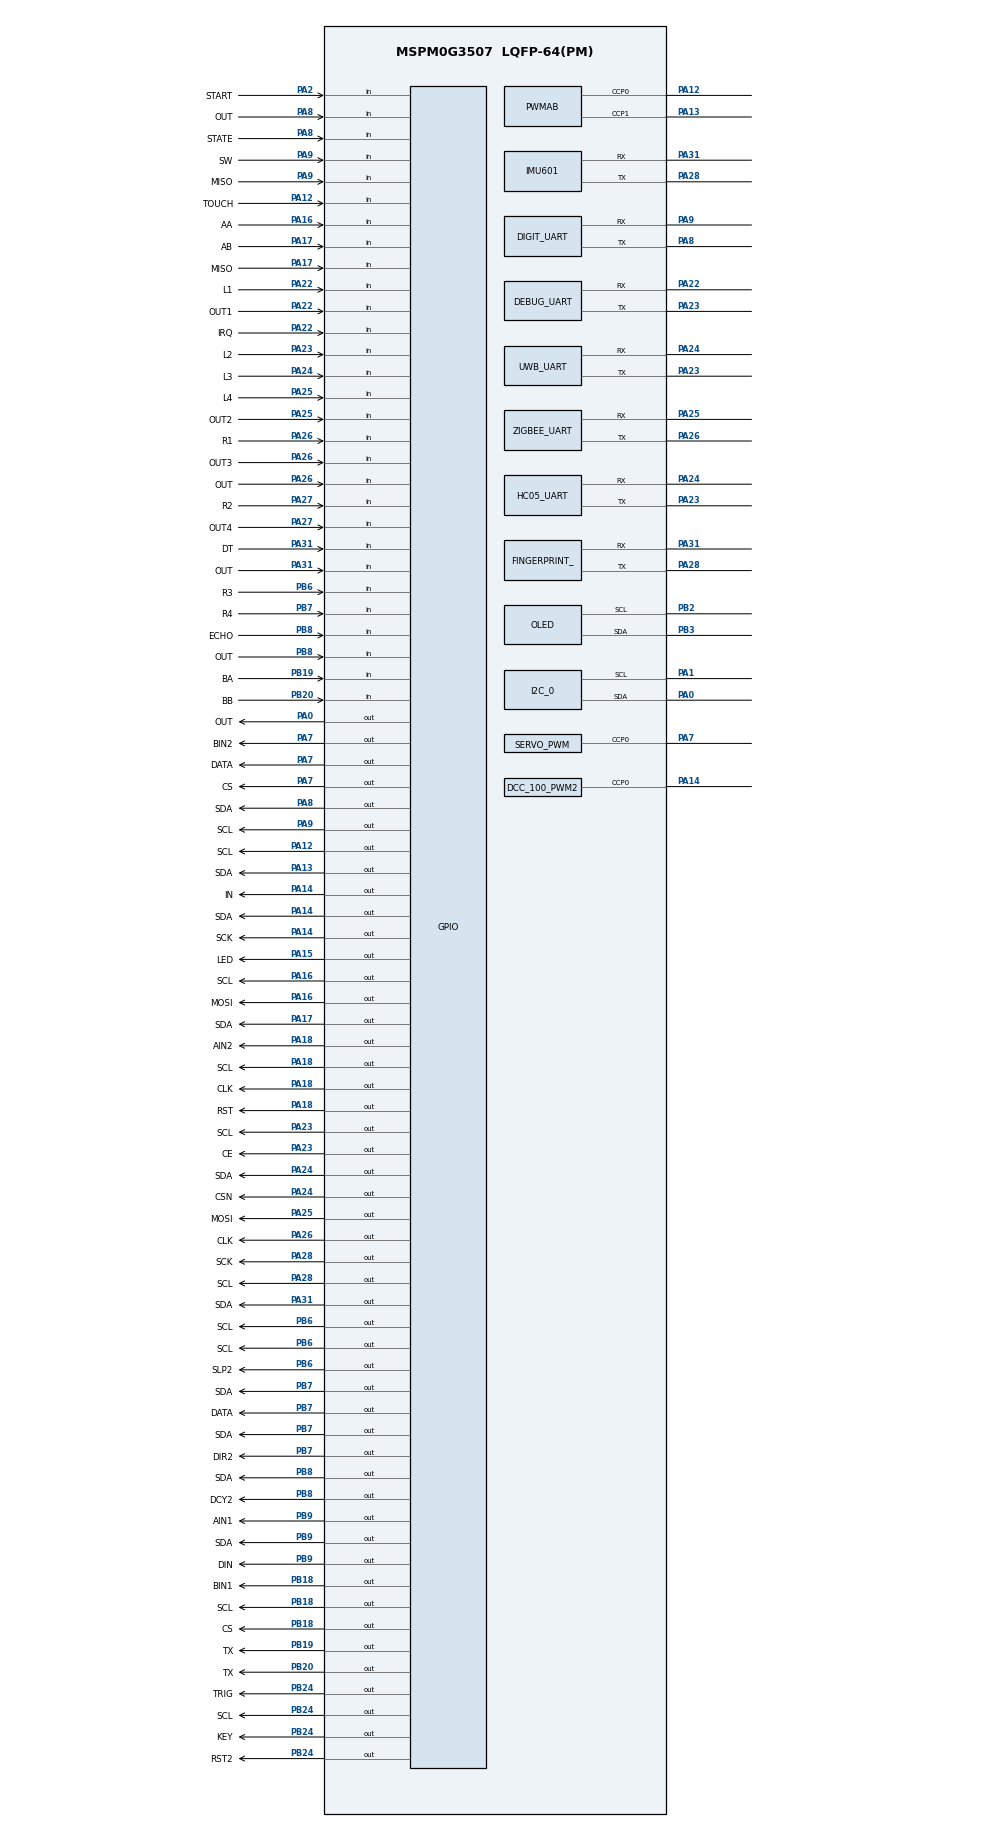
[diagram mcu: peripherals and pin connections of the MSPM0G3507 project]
/**
 * firstep mspm0 母版默认外设布局（地猛星 LCKFB-DMX 开发板，模块库默认引脚方案，
 * 编译闭环用；2026-08-14 地猛星化，工单 mspm0-master-dimx/01）。
 * 实例名/宏名与模块库代码一一对应（PWMAB/DC_MOTOR/IMU601/OLED/NTB/MOTOR_PID/
 * HUIDU/KEY/LED_BEEP/STEP_MOTOR/DCC_100_PWM2/I2C_0）；实际接线不同时改引脚名
 * 即可，实例名与宏名勿动。
 * 引脚方案（除 PB4/PB5 外全部在地猛星 2×20 排针上）：
 *   motor：PWMAB C0/C1→PA12/PA13、DC_MOTOR AIN1=PB9 AIN2=PA18 BIN1=PB18
 *   BIN2=PA7、编码器 AA=PA16 AB=PA17 BA=PB19 BB=PB20
 *   HUIDU：PA22-27/PB4/PB5（R3/R4 的 PB4/PB5 为 LaunchPad 遗留，地猛星未引出）
 *   KEY：PA2（板载 ROSC 偏置 100k 到地，按键与上拉共用此脚）
 *   LED_BEEP：PA15；IR_BEAM：PA8（红外对射 OUT，ir_beam 模块；与
 *   DIGIT_UART 默认重叠，同选时经引脚绑定消解）；IMU601：UART0 =
 *   PA28(TX)/PA31(RX)（板载 CH340E 占
 *   UART0 的 PA10/PA11，勿用）；DIGIT_UART：UART1 = PA8(TX)/PA9(RX)（K230 串口）
 *   OLED：I2C1 = PB3(SDA)/PB2(SCL)；I2C_0：I2C0 = PA0(SDA)/PA1(SCL)（MPU6050，
 *   复用板载 LED 脚——总线空闲高电平 LED 不亮，通信期间微闪；PA1 板载 4.7k 上拉，
 *   PA0 上拉未焊 R12，靠 MPU 板自带）
 *   STEP_MOTOR：RST2/SLP2/DIR2/DCY2 = PB24/PB6/PB7/PB8（全 GPIOB，
 *   STEP_MOTOR_PORT 整组 GPIOB）；DCC_100_PWM2：TIMG12 C0 = PA14（板上经
 *   LED2+15k 到地，PWM 输出时 LED 微亮，可忽略）
 *   JOYSTICK：SW = PA9（摇杆按键，上拉输入低有效；与 DIGIT_UART RX 默认
 *   重叠——手动摇杆与 K230 视觉同选概率最低，同选时经引脚绑定消解）；
 *   ADC12_0 八通道：MEM0 = PA24(A0_3) 归 adc 模块（us016/mq2 薄封装共读同槽），
 *   MEM1 = PA26(A0_1) / MEM2 = PA25(A0_2) 归 joystick 摇杆 X/Y（与
 *   ZIGBEE_UART 默认重叠——手动摇杆与无线身份/信标同选概率最低，同选时
 *   经引脚绑定消解；多 MEM 必须 sequence 模式，2026-09-05 SysConfig CLI
 *   实证），MEM3 = PA27(A0_0) 归 ir_distance（与 HUIDU R2 重叠——红外
 *   测距与灰度巡线同选概率最低），MEM4 = PB20(A0_6) 归 mq135、MEM5 =
 *   PB24(A0_5) 归 mq5（两件均独立通道，
 *   与 DC_MOTOR BB/SYN6288 TX、STEP_MOTOR RST2/SR04 TRIG/HC05 KEY/AT24C02 SCL
 *   重叠——MQ 系与运动控制/语音/记录常见同框概率最低；多路气体同选时物理
 *   通道独立、无共读冲突——mq2 为 MEM0 薄封装
 *   共读同槽，2026-09-08 实证 MEM4-7 通道/脚全合法），MEM6 = PA22(A0_7) 归
 *   flame 火焰传感（独立通道——AO 高阻源取剩余通道中唯一无负载脚，与
 *   HUIDU L1/DEBUG_UART RX/NRF24L01 IRQ/TTP224 OUT1 重叠——巡线巡检/无线
 *   链路/触摸面板与火警/灭火不同框、同选概率最低），MEM7 = PA14(A0_12) 归
 *   soil 土壤湿度（独立通道——**MEM 槽位已满（8/8）**：后续 ADC 类件一律
 *   薄封装共读 MEM0（mq2/us016 先例，多件同选同读一物理通道）；PA14 板载
 *   LED2+15k 为固定比率衰减（读数系统偏小、单调性保留），与步进/灯带/读卡/
 *   气体重叠——浇花/农业与运动/读卡不同框、同选概率最低）
 *   HC05：HC05_UART = UART2 共享（9600——HC05 出厂默认波特率，与 DEBUG+UWB
 *   同外设；默认 PA23/PA24 与 UWB 同脚——蓝牙与 UWB 链路互替、同选概率
 *   最低，同选时经引脚绑定换实例消解）；STATE = PA8 输入（连接状态，
 *   高有效；与 DIGIT_UART TX/IR_BEAM OUT 重叠——蓝牙与 K230 视觉/红外对射
 *   链路互替）、KEY = PB24 输出（AT 模式切换，与 STEP_MOTOR RST2/SR04 TRIG
 *   重叠——AT 切换不常用，同选经引脚绑定消解）
 *   NRF24L01：软 SPI 6 脚全 GPIOA（CLK=PA26/MOSI=PA25/MISO=PA9/
 *   CSN=PA24/CE=PA23/IRQ=PA22，单 NRF24L01_PORT 宏）——与 ZIGBEE_UART/
 *   UWB/DEBUG_UART/HUIDU 巡线/joystick/adc/DIGIT 默认重叠：NRF 与其它无线
 *   链路互替、同选概率最低，同选时经引脚绑定消解；IRQ 输入不配中断（GPIO
 *   中断只有 GROUP1 一路且被 motor 编码器独占，第二个 GROUP1_IRQHandler 会
 *   链接期冲突——按手册轮询方式接收，见 nrf24l01 模块注释）
 *   IR_REMOTE：OUT = PA26 输入（红外接收头，NEC 忙等解码不占 TIMER；
 *   与 ZIGBEE_TX/joystick X/NRF24L01 CLK 重叠——红外与其它无线/手动输入
 *   互替、同选概率最低，同选时经引脚绑定消解；主循环轮询解码，不注册
 *   GPIO 中断，原因同 NRF24L01）
 *   MAX7219：DIN=PB9/CLK=PA18/CS=PB18 输出（数码管/点阵显示，软 SPI 位
 *   操作不占硬件 SPI——与 DC_MOTOR AIN1/AIN2/BIN1 重叠：大数字显示（计分/
 *   计时/数据牌）与双电机小车同选概率最低，同选时经引脚绑定消解；PA18 兼
 *   BSL 排针脚，作输出无碍）
 *   PCA9685：SCL=PB6/SDA=PB7（16 路舵机驱动板，软 I2C 位操作不占硬件 I2C
 *   外设，SDA 方向运行时切换——与 STEP_MOTOR SLP2/DIR2、HUIDU R3/R4、
 *   AHT10/DHT11 温湿度重叠：多路舵机多自由度执行与温湿度采集/步进（互替）/
 *   巡线车同选概率最低，同选时经引脚绑定消解；软 I2C 需板上/模块自带上拉）
 *   IR_TX：OUT = PA0 输出（红外编码发射，38kHz 载波忙等不占 TIMER——与
 *   I2C_0 SDA（ml_mpu6050 姿态）/板载 LED 重叠：红外发射链与姿态采集同选
 *   概率最低，板载 LED 随载波闪烁可作发射指示；与 IR_REMOTE 默认 PA26 刻意
 *   错开——发射/接收常配对，双选默认即不撞，同选时经引脚绑定消解）
 * 板上固定占用：CH340E PA10/PA11、Flash PB14-17、晶振 PA3-6、板载 LED PA0/PA1、
 * VREF- PA21 直连地、BSL PA18（47k 到 BSL 排针）、SWD PA19/PA20（独立 DEBUG 排针，
 * 用户实物未在 2×20P 上找到 A19/A20）、NRST。2026-08-20 用户实物核验：芯片丝印
 * 可见 42WG4 / ABDL，外周为 48 脚，2×20P 排针分布正确，PA13/PA14 在排针上可用。
 * TI 封装命名中 LQFP(PT)=48 脚、LQFP(PM)=64 脚；当前 SysConfig 仍沿用可工作的
 * LQFP-64(PM) / LP-MSPM0G3507 模型，不以此反推实物脚数。实际地猛星 2×20P
 * 引出范围由 mspm0-dimx 板定义约束，PB4/PB5 为 LaunchPad 遗留模型脚、不在 2×20P 上。
 */
//@cliArgs --device "MSPM0G350X" --package "LQFP-64(PM)" --part "Default"
//@v2CliArgs --device "MSPM0G3507" --package "LQFP-64(PM)"
// @cliArgs --board /ti/boards/LP_MSPM0G3507 --rtos nortos

/**
 * Import the modules used in this configuration.
 */
const PWM     = scripting.addModule("/ti/driverlib/PWM", {}, false);
const PWMAB   = PWM.addInstance();
const DCC_100_PWM2 = PWM.addInstance();
// 舵机（servo 模块：50Hz/20ms 周期，0.5-2.5ms 脉宽映射 0-180°；周期由
// servo_init 按 SERVO_PWM_INST_CLK_FREQ 运行时配置，此处初值仅保证可编译）
const SERVO_PWM = PWM.addInstance();
SERVO_PWM.$name                      = "SERVO_PWM";
SERVO_PWM.clockPrescale              = 1;
SERVO_PWM.timerCount                 = 65535;
SERVO_PWM.peripheral.$assign         = "TIMG8";
SERVO_PWM.peripheral.ccp0Pin.$assign = "PA7";
const TIMER   = scripting.addModule("/ti/driverlib/TIMER", {}, false);
const MOTOR_PID = TIMER.addInstance();
const NTB     = TIMER.addInstance();
const GPIO    = scripting.addModule("/ti/driverlib/GPIO", {}, false);
const DC_MOTOR = GPIO.addInstance();
const HUIDU   = GPIO.addInstance();
const KEY     = GPIO.addInstance();
const WS2812 = GPIO.addInstance();
const HX711 = GPIO.addInstance();
const AHT10 = GPIO.addInstance();
const SR04 = GPIO.addInstance();
const JOYSTICK = GPIO.addInstance();
const HC05 = GPIO.addInstance();
const NRF24L01 = GPIO.addInstance();
const IR_REMOTE = GPIO.addInstance();
const LED_BEEP = GPIO.addInstance();
const STEP_MOTOR = GPIO.addInstance();
const IR_BEAM = GPIO.addInstance();
const UART    = scripting.addModule("/ti/driverlib/UART", {}, false);
const IMU601  = UART.addInstance();
const I2C     = scripting.addModule("/ti/driverlib/I2C", {}, false);
const OLED    = I2C.addInstance();
const I2C_0   = I2C.addInstance();
const SYSCTL  = scripting.addModule("/ti/driverlib/SYSCTL");

/**
 * Write custom configuration values to the imported modules.
 */

// 电机 PWM：双通道 C0/C1（TB6612 左/右 PWM 输入）
PWMAB.$name                      = "PWMAB";
PWMAB.clockPrescale              = 256;
PWMAB.timerCount                 = 2000;
PWMAB.peripheral.$assign         = "TIMG0";
PWMAB.peripheral.ccp0Pin.$assign = "PA12";
PWMAB.peripheral.ccp1Pin.$assign = "PA13";
PWMAB.PWM_CHANNEL_0.$name        = "ti_driverlib_pwm_PWMTimerCC0";
PWMAB.PWM_CHANNEL_0.dutyCycle    = 0;
PWMAB.PWM_CHANNEL_1.$name        = "ti_driverlib_pwm_PWMTimerCC1";
PWMAB.PWM_CHANNEL_1.dutyCycle    = 0;

// 步进电机脉冲输出（step_motor 模块：DCC_100_PWM2_INST，TIMG12 32 位定时器，
// clockPrescale 必须为 1——step_set_speed 按 INST_CLK_FREQ/频率 直算周期；C0 = PA14）
DCC_100_PWM2.$name              = "DCC_100_PWM2";
DCC_100_PWM2.clockPrescale      = 1;
DCC_100_PWM2.timerCount         = 65535;
DCC_100_PWM2.peripheral.$assign = "TIMG12";
DCC_100_PWM2.peripheral.ccp0Pin.$assign = "PA14";
DCC_100_PWM2.PWM_CHANNEL_0.$name        = "ti_driverlib_pwm_DCC100_CC0";
DCC_100_PWM2.PWM_CHANNEL_0.dutyCycle    = 50;

// 电机 PID 调度定时器（10ms 周期中断，pid 模块用；编译闭环只需宏存在）
MOTOR_PID.$name              = "MOTOR_PID";
MOTOR_PID.profile            = "Basic_Periodic";
MOTOR_PID.peripheral.$assign = "TIMG6";

// 计程定时器（ntb_time 模块读计数）
NTB.$name              = "NTB";
NTB.profile            = "Basic_Periodic";
NTB.peripheral.$assign = "TIMG7";

// 超声波 TRIG/ECHO（sr04 模块：TRIG 输出触发 / ECHO 输入回波；测宽用
// CPU 忙等计数，不占 TIMER 外设——地猛星 SysConfig TIMER 实例仅暴露
// TIMG0/6/7/8/12（已被 motor/pid/ntb_time/servo/step_motor 全占，没有
// 新定时器可加）。默认 TRIG=PB24（与 STEP_MOTOR RST2 重叠）、ECHO=PB8
// （与 STEP_MOTOR DCY2 重叠）——测距与步进同选概率最低，同选时经引脚
// 绑定消解）
SR04.$name = "SR04";
SR04.associatedPins.create(2);
SR04.associatedPins[0].$name        = "TRIG";
SR04.associatedPins[0].direction    = "OUTPUT";
SR04.associatedPins[0].initialValue = "CLEARED";
SR04.associatedPins[0].pin.$assign  = "PB24";
SR04.associatedPins[1].$name        = "ECHO";
SR04.associatedPins[1].direction    = "INPUT";
SR04.associatedPins[1].pin.$assign  = "PB8";

// 电机方向/使能 + 编码器中断（key 模块 GROUP1_IRQHandler 消费 IIDX）
DC_MOTOR.$name = "DC_MOTOR";
DC_MOTOR.associatedPins.create(8);
DC_MOTOR.associatedPins[0].$name        = "AIN1";
DC_MOTOR.associatedPins[0].direction    = "OUTPUT";
DC_MOTOR.associatedPins[0].initialValue = "CLEARED";
DC_MOTOR.associatedPins[0].pin.$assign  = "PB9";
DC_MOTOR.associatedPins[1].$name        = "AIN2";
DC_MOTOR.associatedPins[1].direction    = "OUTPUT";
DC_MOTOR.associatedPins[1].initialValue = "CLEARED";
DC_MOTOR.associatedPins[1].pin.$assign  = "PA18";
DC_MOTOR.associatedPins[2].$name        = "BIN1";
DC_MOTOR.associatedPins[2].direction    = "OUTPUT";
DC_MOTOR.associatedPins[2].initialValue = "CLEARED";
DC_MOTOR.associatedPins[2].pin.$assign  = "PB18";
DC_MOTOR.associatedPins[3].$name        = "BIN2";
DC_MOTOR.associatedPins[3].direction    = "OUTPUT";
DC_MOTOR.associatedPins[3].initialValue = "CLEARED";
DC_MOTOR.associatedPins[3].pin.$assign  = "PA7";
DC_MOTOR.associatedPins[4].$name        = "AA";
DC_MOTOR.associatedPins[4].direction    = "INPUT";
DC_MOTOR.associatedPins[4].interruptEn  = true;
DC_MOTOR.associatedPins[4].polarity     = "RISE_FALL";
DC_MOTOR.associatedPins[4].pin.$assign  = "PA16";
DC_MOTOR.associatedPins[5].$name        = "AB";
DC_MOTOR.associatedPins[5].direction    = "INPUT";
DC_MOTOR.associatedPins[5].interruptEn  = true;
DC_MOTOR.associatedPins[5].polarity     = "RISE_FALL";
DC_MOTOR.associatedPins[5].pin.$assign  = "PA17";
DC_MOTOR.associatedPins[6].$name        = "BA";
DC_MOTOR.associatedPins[6].direction    = "INPUT";
DC_MOTOR.associatedPins[6].interruptEn  = true;
DC_MOTOR.associatedPins[6].polarity     = "RISE_FALL";
DC_MOTOR.associatedPins[6].pin.$assign  = "PB19";
DC_MOTOR.associatedPins[7].$name        = "BB";
DC_MOTOR.associatedPins[7].direction    = "INPUT";
DC_MOTOR.associatedPins[7].interruptEn  = true;
DC_MOTOR.associatedPins[7].polarity     = "RISE_FALL";
DC_MOTOR.associatedPins[7].pin.$assign  = "PB20";

// 8 路灰度循线输入（引脚空闲位，按实际接线改）
HUIDU.$name = "HUIDU";
HUIDU.associatedPins.create(8);
HUIDU.associatedPins[0].$name       = "L1";
HUIDU.associatedPins[0].direction   = "INPUT";
HUIDU.associatedPins[0].pin.$assign = "PA22";
HUIDU.associatedPins[1].$name       = "L2";
HUIDU.associatedPins[1].direction   = "INPUT";
HUIDU.associatedPins[1].pin.$assign = "PA23";
HUIDU.associatedPins[2].$name       = "L3";
HUIDU.associatedPins[2].direction   = "INPUT";
HUIDU.associatedPins[2].pin.$assign = "PA24";
HUIDU.associatedPins[3].$name       = "L4";
HUIDU.associatedPins[3].direction   = "INPUT";
HUIDU.associatedPins[3].pin.$assign = "PA25";
HUIDU.associatedPins[4].$name       = "R1";
HUIDU.associatedPins[4].direction   = "INPUT";
HUIDU.associatedPins[4].pin.$assign = "PA26";
HUIDU.associatedPins[5].$name       = "R2";
HUIDU.associatedPins[5].direction   = "INPUT";
HUIDU.associatedPins[5].pin.$assign = "PA27";
HUIDU.associatedPins[6].$name       = "R3";
HUIDU.associatedPins[6].direction   = "INPUT";
HUIDU.associatedPins[6].pin.$assign = "PB6";
HUIDU.associatedPins[7].$name       = "R4";
HUIDU.associatedPins[7].direction   = "INPUT";
HUIDU.associatedPins[7].pin.$assign = "PB7";

// 启动按键输入（实例名 KEY → KEY_PORT 宏；引脚名 START → KEY_START_PIN）
KEY.$name = "KEY";
KEY.associatedPins.create(1);
KEY.associatedPins[0].$name       = "START";
KEY.associatedPins[0].direction   = "INPUT";
KEY.associatedPins[0].pin.$assign = "PA2";

// 红外对射传感器输入（ir_beam 模块：实例名 IR_BEAM → IR_BEAM_PORT 宏；
// 引脚名 OUT → IR_BEAM_OUT_PIN；默认 PA8——仅与 DIGIT_UART 默认重叠，
// 同选时经引脚绑定消解；内部上拉 = 遮挡（开集输出截止）时由电阻钳到高，
// 无遮挡 = 接收管导通拉低）
IR_BEAM.$name = "IR_BEAM";
IR_BEAM.associatedPins.create(1);
IR_BEAM.associatedPins[0].$name            = "OUT";
IR_BEAM.associatedPins[0].direction        = "INPUT";
IR_BEAM.associatedPins[0].internalResistor = "PULL_UP";
IR_BEAM.associatedPins[0].pin.$assign      = "PA8";

// WS2812 幻彩灯带数据脚（ws2812 模块：单 GPIO 强推挽输出，位操作时序；
// 默认 PA14——与 DCC_100_PWM2（step_motor 脉冲）默认重叠，同选时经引脚
// 绑定消解。地猛星 2×20 排针 31 个 IO 已被母版默认布局全占，新模块默认
// 脚按「与同选概率最低者重叠」分配，IR_BEAM/PA8 先例）
WS2812.$name = "WS2812";
WS2812.associatedPins.create(1);
WS2812.associatedPins[0].$name        = "IN";
WS2812.associatedPins[0].direction    = "OUTPUT";
WS2812.associatedPins[0].initialValue = "CLEARED";
WS2812.associatedPins[0].pin.$assign  = "PA14";

// HX711 称重（hx711 模块：SCK 输出 / DT 输入（片上拉，空闲高 = 未就绪，
// 数据就绪拉低）。默认 SCK=PA28（与 IMU601 TX 重叠）、DT=PA31（与 IMU601
// RX 重叠）——称重与串口陀螺仪同为「姿态/力」低频组合，同选概率最低；
// 同选时经引脚绑定消解）
HX711.$name = "HX711";
HX711.associatedPins.create(2);
HX711.associatedPins[0].$name        = "SCK";
HX711.associatedPins[0].direction    = "OUTPUT";
HX711.associatedPins[0].initialValue = "CLEARED";
HX711.associatedPins[0].pin.$assign  = "PA28";
HX711.associatedPins[1].$name        = "DT";
HX711.associatedPins[1].direction    = "INPUT";
HX711.associatedPins[1].internalResistor = "PULL_UP";
HX711.associatedPins[1].pin.$assign  = "PA31";

// AHT10 温湿度软 I2C（aht10 模块：SCL 输出 / SDA 双向运行时切换；
// 位操作不占硬件 I2C 外设。默认 SCL=PB6（与 STEP_MOTOR SLP2 / HUIDU R3
// 重叠）、SDA=PB7（与 STEP_MOTOR DIR2 / HUIDU R4 重叠）——温湿度与步进/
// 巡线同选概率最低，同选时经引脚绑定消解；软 I2C 需板上/模块自带上拉）
AHT10.$name = "AHT10";
AHT10.associatedPins.create(2);
AHT10.associatedPins[0].$name        = "SCL";
AHT10.associatedPins[0].direction    = "OUTPUT";
AHT10.associatedPins[0].initialValue = "CLEARED";
AHT10.associatedPins[0].pin.$assign  = "PB6";
AHT10.associatedPins[1].$name        = "SDA";
AHT10.associatedPins[1].direction    = "OUTPUT";
AHT10.associatedPins[1].initialValue = "CLEARED";
AHT10.associatedPins[1].pin.$assign  = "PB7";

// DHT11 单总线温湿度（dht11 模块：DATA 双向——输出起始信号/释放总线、
// 输入采样响应与 40bit 数据位，方向运行时切换（照 AHT10_SDA 先例）；
// 位时序 CPU 忙等 + delay 模块换算，不占 TIMER。默认 DATA=PB7——与
// AHT10 SDA（温湿度互替、同选概率最低）/STEP_MOTOR DIR2/HUIDU R4
// 重叠（温湿度与步进/巡线同选概率最低，AHT10 先例），同选时经引脚绑定消解）
const DHT11 = GPIO.addInstance();
DHT11.$name = "DHT11";
DHT11.associatedPins.create(1);
DHT11.associatedPins[0].$name        = "DATA";
DHT11.associatedPins[0].direction    = "OUTPUT";
DHT11.associatedPins[0].initialValue = "SET";
DHT11.associatedPins[0].pin.$assign  = "PB7";

// DS18B20 单总线温度（ds18b20 模块：DATA 双向——输出起始/释放总线、输入采样
// 应答与数据位，方向运行时切换（照 DHT11_DATA 先例）；位时序 CPU 忙等 +
// delay 模块换算（复位 750us、位槽 62-64us），不占 TIMER；模块板自带上拉。
// 默认 DATA=PA7——与 DC_MOTOR BIN2（双电机）、SERVO_PWM ccp0（舵机）、
// RC522 CS（读卡门禁）重叠：接触测温与运动控制/读卡不同框、同选概率最低
// （刻意不叠温湿度/光照/显示/语音件——测温+显示/语音/传感站为常见搭配，
// 同 mlx90614 选型口诀；也不叠 I2C_0 的 PA0/PA1——硬件 I2C 脚与 i2c_bus_share
// 测试互扰，批次 5 实测调整先例），同选时经引脚绑定消解）
const DS18B20 = GPIO.addInstance();
DS18B20.$name = "DS18B20";
DS18B20.associatedPins.create(1);
DS18B20.associatedPins[0].$name        = "DATA";
DS18B20.associatedPins[0].direction    = "OUTPUT";
DS18B20.associatedPins[0].initialValue = "SET";
DS18B20.associatedPins[0].pin.$assign  = "PA7";

// BH1750 光照度软 I2C（bh1750 模块：SCL 输出 / SDA 双向运行时切换；
// 位操作不占硬件 I2C 外设，照 AHT10 先例。默认 SCL=PA12 / SDA=PA13——
// 与 PWMAB C0/C1（motor 双路 PWM）重叠：光照度监测/台灯类与双电机驱动
// 同选概率最低（故意不叠 AHT10 的 PB6/PB7——温湿度+光照=环境监测站常见
// 组合），同选时经引脚绑定消解；软 I2C 需板上/模块自带上拉）
const BH1750 = GPIO.addInstance();
BH1750.$name = "BH1750";
BH1750.associatedPins.create(2);
BH1750.associatedPins[0].$name        = "SCL";
BH1750.associatedPins[0].direction    = "OUTPUT";
BH1750.associatedPins[0].initialValue = "CLEARED";
BH1750.associatedPins[0].pin.$assign  = "PA12";
BH1750.associatedPins[1].$name        = "SDA";
BH1750.associatedPins[1].direction    = "OUTPUT";
BH1750.associatedPins[1].initialValue = "CLEARED";
BH1750.associatedPins[1].pin.$assign  = "PA13";

// ADS1115 四通道 16bit 外扩 ADC（ads1115 模块：软 I2C 位操作 2 脚 SCL/SDA——
// 照 AHT10 先例不占硬件 I2C 外设；SDA 方向运行时切换（写 = 输出、读 ACK = 输入）。
// 默认 SCL=PA16 / SDA=PA17——与 DC_MOTOR 编码器 AA/AB、RC522 MOSI/MISO 重叠：
// 外扩多通道 ADC 与双电机闭环车/读卡门禁同选概率最低（与库内 adc 板载 12bit
// 单通道分工不同：adc = 板载 ADC12_0 MEM0（默认 PA24，us016 共读同槽），多路
// 模拟量/分离供电用本件——两件同选互不冲突），同选时经引脚绑定消解；
// 软 I2C 需板上/模块自带上拉）
const ADS1115 = GPIO.addInstance();
ADS1115.$name = "ADS1115";
ADS1115.associatedPins.create(2);
ADS1115.associatedPins[0].$name        = "SCL";
ADS1115.associatedPins[0].direction    = "OUTPUT";
ADS1115.associatedPins[0].initialValue = "CLEARED";
ADS1115.associatedPins[0].pin.$assign  = "PA16";
ADS1115.associatedPins[1].$name        = "SDA";
ADS1115.associatedPins[1].direction    = "OUTPUT";
ADS1115.associatedPins[1].initialValue = "CLEARED";
ADS1115.associatedPins[1].pin.$assign  = "PA17";

// TCS34725 颜色识别（tcs34725 模块：软 I2C 位操作 2 脚 SCL/SDA——照 AHT10 先例
// 不占硬件 I2C 外设；SDA 方向运行时切换（写 = 输出、读 ACK = 输入）。默认
// SCL=PA23 / SDA=PA24——与 HUIDU L2/L3、UWB/DEBUG/HC05 UART（PA23/PA24）、
// NRF24L01 CSN/CE、ADC12_0 MEM0（adc+us016 共享槽）重叠：颜色识别与无线
// 链路/巡线/板载 ADC 同选概率最低（颜色识别属视觉类，与 K230 视觉互替；
// 刻意不叠 OLED PB2/PB3/MAX7219 显示件——显示颜色值是常见搭配），同选时
// 经引脚绑定消解；软 I2C 需板上/模块自带上拉）
const TCS34725 = GPIO.addInstance();
TCS34725.$name = "TCS34725";
TCS34725.associatedPins.create(2);
TCS34725.associatedPins[0].$name        = "SCL";
TCS34725.associatedPins[0].direction    = "OUTPUT";
TCS34725.associatedPins[0].initialValue = "CLEARED";
TCS34725.associatedPins[0].pin.$assign  = "PA23";
TCS34725.associatedPins[1].$name        = "SDA";
TCS34725.associatedPins[1].direction    = "OUTPUT";
TCS34725.associatedPins[1].initialValue = "CLEARED";
TCS34725.associatedPins[1].pin.$assign  = "PA24";

// MLX90614 非接触红外测温（mlx90614 模块：软 I2C/SMBus 兼容位操作 2 脚
// SCL/SDA——照 AHT10 先例不占硬件 I2C 外设；SDA 方向运行时切换（写 = 输出、
// 读 ACK = 输入）。默认 SCL=PA9 / SDA=PA8——与 DIGIT_UART RX/TX（K230 视觉）、
// IR_BEAM OUT、HC05 STATE、JOYSTICK SW、NRF24L01 MISO 重叠：非接触测温与
// 视觉（K230 互替类）/手动输入/蓝牙/2.4G 链路同选概率最低（刻意不叠
// 温湿度/光照/显示——测温与传感站/显示为常见搭配），同选时经引脚绑定
// 消解；软 I2C 需板上/模块自带上拉（SMBus 上拉 4.7k~10k，模块板自带））
const MLX90614 = GPIO.addInstance();
MLX90614.$name = "MLX90614";
MLX90614.associatedPins.create(2);
MLX90614.associatedPins[0].$name        = "SCL";
MLX90614.associatedPins[0].direction    = "OUTPUT";
MLX90614.associatedPins[0].initialValue = "CLEARED";
MLX90614.associatedPins[0].pin.$assign  = "PA9";
MLX90614.associatedPins[1].$name        = "SDA";
MLX90614.associatedPins[1].direction    = "OUTPUT";
MLX90614.associatedPins[1].initialValue = "CLEARED";
MLX90614.associatedPins[1].pin.$assign  = "PA8";

// AT24C02 EEPROM 存储（at24c02 模块：软 I2C 位操作 2 脚 SCL/SDA——照 AHT10
// 先例不占硬件 I2C 外设；SDA 方向运行时切换（写 = 输出、读 ACK = 输入）。
// 默认 SCL=PB24 / SDA=PB8——与 STEP_MOTOR RST2/DCY2、SR04 TRIG/ECHO、
// HC05 KEY 重叠：EEPROM 存储记录与步进/测距同选概率最低（记录类与运动类
// 不同框；记录+传感站类同选时与同批 ads1115/tcs34725/mlx90614 默认不撞），
// 同选时经引脚绑定消解；软 I2C 需板上/模块自带上拉）
const AT24C02 = GPIO.addInstance();
AT24C02.$name = "AT24C02";
AT24C02.associatedPins.create(2);
AT24C02.associatedPins[0].$name        = "SCL";
AT24C02.associatedPins[0].direction    = "OUTPUT";
AT24C02.associatedPins[0].initialValue = "CLEARED";
AT24C02.associatedPins[0].pin.$assign  = "PB24";
AT24C02.associatedPins[1].$name        = "SDA";
AT24C02.associatedPins[1].direction    = "OUTPUT";
AT24C02.associatedPins[1].initialValue = "CLEARED";
AT24C02.associatedPins[1].pin.$assign  = "PB8";

// SHT30 温湿度软 I2C（sht30 模块：SCL 输出 / SDA 双向运行时切换；
// 位操作不占硬件 I2C 外设，照 AHT10 先例——半周期 5us ≈ 100kHz 级。
// 默认 SCL=PA28 / SDA=PA31——与 IMU601 UART0（+FINGERPRINT_UART）、
// HX711 SCK/DT 重叠：温湿度与姿态/称重/身份采集不同框、同选概率最低
// （刻意不叠 PB6/PB7——aht10 温湿度互替；不叠批次 5 八脚），同选时经引脚
// 绑定消解；软 I2C 需板上/模块自带上拉）
const SHT30 = GPIO.addInstance();
SHT30.$name = "SHT30";
SHT30.associatedPins.create(2);
SHT30.associatedPins[0].$name        = "SCL";
SHT30.associatedPins[0].direction    = "OUTPUT";
SHT30.associatedPins[0].initialValue = "CLEARED";
SHT30.associatedPins[0].pin.$assign  = "PA28";
SHT30.associatedPins[1].$name        = "SDA";
SHT30.associatedPins[1].direction    = "OUTPUT";
SHT30.associatedPins[1].initialValue = "CLEARED";
SHT30.associatedPins[1].pin.$assign  = "PA31";

// SGP30 空气 TVOC/CO2e 气体传感（sgp30 模块：软 I2C 位操作 2 脚 SCL/SDA——
// 照 AHT10 先例不占硬件 I2C 外设；SDA 方向运行时切换（写 = 输出、读 ACK =
// 输入）。默认 SCL=PA18 / SDA=PB9——与 DC_MOTOR AIN2/AIN1（双电机）、
// MAX7219 CLK/DIN（大数字显示）、RC522 RST（读卡门禁）重叠：气体传感与
// 运动控制/读卡门禁不同框、同选概率最低（刻意不叠温湿度（AHT10 PB6/PB7、
// DHT11 PB7、DS18B20 PA7、SHT30 PA28/PA31）、光照（PA12/PA13）、OLED 显示
// （PB2/PB3）、语音（PB19/PB20）、按键（PA2、PA22-27）、报警（PA15）、无线
// （PA8/PA9/PA23/PA24）与批次 5 八脚——气体检测器标配温湿度+显示+蜂鸣/灯+
// 键盘，同选概率最高故避开），同选时经引脚绑定消解；软 I2C 需板上/模块
// 自带上拉）
const SGP30 = GPIO.addInstance();
SGP30.$name = "SGP30";
SGP30.associatedPins.create(2);
SGP30.associatedPins[0].$name        = "SCL";
SGP30.associatedPins[0].direction    = "OUTPUT";
SGP30.associatedPins[0].initialValue = "CLEARED";
SGP30.associatedPins[0].pin.$assign  = "PA18";
SGP30.associatedPins[1].$name        = "SDA";
SGP30.associatedPins[1].direction    = "OUTPUT";
SGP30.associatedPins[1].initialValue = "CLEARED";
SGP30.associatedPins[1].pin.$assign  = "PB9";

// AGS10 有害气体（TVOC）传感（ags10 模块：软 I2C 位操作 2 脚 SCL/SDA——
// 照 AHT10 先例不占硬件 I2C 外设；SDA 方向运行时切换（写 = 输出、读 ACK =
// 输入）。默认 SCL=PB18 / SDA=PA14——与 DC_MOTOR BIN1（双电机）、MAX7219 CS
// （大数字显示）、DCC_100_PWM2（step_motor 步进脉冲——风机排烟联动）、
// WS2812 IN（灯带指示）、RC522 SCK（读卡门禁）重叠：气体传感与运动控制/读卡/
// 灯带低频同框、同选概率最低（避让原则同 SGP30：不叠温湿度/光照/OLED/语音/
// 按键/报警/无线/批次 5 八脚），同选时经引脚绑定消解；软 I2C 需板上/模块
// 自带上拉）
const AGS10 = GPIO.addInstance();
AGS10.$name = "AGS10";
AGS10.associatedPins.create(2);
AGS10.associatedPins[0].$name        = "SCL";
AGS10.associatedPins[0].direction    = "OUTPUT";
AGS10.associatedPins[0].initialValue = "CLEARED";
AGS10.associatedPins[0].pin.$assign  = "PB18";
AGS10.associatedPins[1].$name        = "SDA";
AGS10.associatedPins[1].direction    = "OUTPUT";
AGS10.associatedPins[1].initialValue = "CLEARED";
AGS10.associatedPins[1].pin.$assign  = "PA14";

// TTP224 4 路电容触摸按键（ttp224 模块：OUT1-4 输入 + 内部上拉——页面
// 「上拉输入」；电平直读无去抖/无 GPIO 中断（GROUP1 仍被 motor 编码器独占，
// 页面同为电平直读）。默认 OUT1=PA22 / OUT2=PA25 / OUT3=PA26 / OUT4=PA27——
// 与 HUIDU L1/L4/R1/R2（巡线）、DEBUG_UART RX/NRF24L01 IRQ、ZIGBEE_UART/
// joystick X-Y/IR_REMOTE/ADC12_0 MEM3（ir_distance）重叠：触摸按键与无线
// 链路/手动输入互替、与巡线/测距不同框，同选概率最低；四脚与同批默认
// （PA7/PA28/PA31/PA24）不撞，同选时经引脚绑定消解）
const TTP224 = GPIO.addInstance();
TTP224.$name = "TTP224";
TTP224.associatedPins.create(4);
TTP224.associatedPins[0].$name            = "OUT1";
TTP224.associatedPins[0].direction        = "INPUT";
TTP224.associatedPins[0].internalResistor = "PULL_UP";
TTP224.associatedPins[0].pin.$assign      = "PA22";
TTP224.associatedPins[1].$name            = "OUT2";
TTP224.associatedPins[1].direction        = "INPUT";
TTP224.associatedPins[1].internalResistor = "PULL_UP";
TTP224.associatedPins[1].pin.$assign      = "PA25";
TTP224.associatedPins[2].$name            = "OUT3";
TTP224.associatedPins[2].direction        = "INPUT";
TTP224.associatedPins[2].internalResistor = "PULL_UP";
TTP224.associatedPins[2].pin.$assign      = "PA26";
TTP224.associatedPins[3].$name            = "OUT4";
TTP224.associatedPins[3].direction        = "INPUT";
TTP224.associatedPins[3].internalResistor = "PULL_UP";
TTP224.associatedPins[3].pin.$assign      = "PA27";

// 人体红外感应输入（human_ir 模块：OUT 输入 + 内部上拉——HC-SR501 模块被
// 感应到人体时输出高电平（模块介绍「人进入其感应范围则输出高电平」+ 规格
// 「电平输出：高3.3V/低0V」；页面函数注释「0=感应到」与介绍矛盾——按
// HC-SR501 器件标准高=检测到修正，模块 notes 记录）；电平直读无去抖/无
// GPIO 中断（GROUP1 仍被 motor 编码器独占，页面同为电平直读）。默认 PB8——
// 与 STEP_MOTOR DCY2 / SR04 ECHO / AT24C02 SDA 重叠：人体红外与步进/测距/
// 存储不同框、同选概率最低（感应灯/防盗报警惯配温湿度/光照/显示/语音/无线/
// 按键/蜂鸣——刻意不叠），同选时经引脚绑定消解）
const HUMAN_IR = GPIO.addInstance();
HUMAN_IR.$name = "HUMAN_IR";
HUMAN_IR.associatedPins.create(1);
HUMAN_IR.associatedPins[0].$name            = "OUT";
HUMAN_IR.associatedPins[0].direction        = "INPUT";
HUMAN_IR.associatedPins[0].internalResistor = "PULL_UP";
HUMAN_IR.associatedPins[0].pin.$assign      = "PB8";

// 微波多普勒雷达输入（microwave_radar 模块：OUT 输入 + 内部上拉——HB100
// 模块检测到物体移动时 OUT 低电平（页面函数注释「1=未检测到 0=检测到」+
// main 演示（OUT 输入为 0 判移动）同口径，页面自一致）；电平直读无去抖/无
// GPIO 中断（GROUP1 仍被 motor 编码器独占，页面同为电平直读）；页面演示的
// 开/关门时序逻辑归生成骨架（ADR 0009）。默认 PA31——2026-09-09 SysConfig
// CLI 实证 PA0/PA1 不在 GPIO 输入实例 pin 选项内（"No option named PA0
// defined"；GPIO 输出可配 PA0——ir_remote_tx 先例，输入不可）→ 改选
// PA31：与 IMU601 RX（姿态）/HX711 DT（称重）/FINGERPRINT_UART RX（身份）/
// SHT30 SDA（温湿度）重叠——微波雷达（自动门/车流/倒车）与姿态/称重/身份/
// 温湿度采集不同框、同选概率最低（自动门/车流惯配电机/显示/蜂鸣/无线/超声/
// 人体红外——刻意不叠：PWMAB/MAX7219/LED_BEEP/无线族/SR04 脚/human_ir PB8），
// 同选时经引脚绑定消解；与同批 human_ir（PB8）刻意错开（人体红外+微波组合
// 常同选，默认即不撞）
const MICROWAVE = GPIO.addInstance();
MICROWAVE.$name = "MICROWAVE";
MICROWAVE.associatedPins.create(1);
MICROWAVE.associatedPins[0].$name            = "OUT";
MICROWAVE.associatedPins[0].direction        = "INPUT";
MICROWAVE.associatedPins[0].internalResistor = "PULL_UP";
MICROWAVE.associatedPins[0].pin.$assign      = "PA31";

// 双轴摇杆按键（joystick 模块：SW 输入上拉低有效；实例名 JOYSTICK →
// JOYSTICK_PORT 宏；引脚名 SW → JOYSTICK_SW_PIN；默认 PA9——仅与
// DIGIT_UART RX 默认重叠（K230 视觉串口），同选时经引脚绑定消解。
// X/Y 两轴走 ADC12_0 MEM1/MEM2（见 ADC 段），SW 独立 GPIO）
JOYSTICK.$name = "JOYSTICK";
JOYSTICK.associatedPins.create(1);
JOYSTICK.associatedPins[0].$name            = "SW";
JOYSTICK.associatedPins[0].direction        = "INPUT";
JOYSTICK.associatedPins[0].internalResistor = "PULL_UP";
JOYSTICK.associatedPins[0].pin.$assign  = "PA9";

// HC05 蓝牙（hc05 模块：STATE 输入 = 连接状态指示（模块 STATE 脚高 = 手机
// 已连接；默认 PA8——与 DIGIT_UART TX / IR_BEAM OUT 默认重叠：K230 视觉/
// 红外对射与蓝牙链路互替，同选时经引脚绑定消解）；KEY 输出 = AT 模式切换
// 按键（KEY 高 + 重上电 = AT 命令模式；默认 PB24——与 STEP_MOTOR RST2 /
// SR04 TRIG 重叠，AT 切换不常用，同选时经引脚绑定消解））
HC05.$name = "HC05";
HC05.associatedPins.create(2);
HC05.associatedPins[0].$name            = "STATE";
HC05.associatedPins[0].direction        = "INPUT";
HC05.associatedPins[0].pin.$assign      = "PA8";
HC05.associatedPins[1].$name            = "KEY";
HC05.associatedPins[1].direction        = "OUTPUT";
HC05.associatedPins[1].initialValue     = "CLEARED";
HC05.associatedPins[1].pin.$assign      = "PB24";

// NRF24L01 2.4G 无线（nrf24l01 模块：软 SPI 位操作 6 脚——CLK/MOSI/CSN/CE
// 输出 + MISO/IRQ 输入；IRQ 输入不配中断（GPIO 中断只有 GROUP1 一路且被
// motor 编码器独占——NRF+电机是双车标配组合，定义第二个 GROUP1_IRQHandler
// 会链接期冲突，按手册轮询方式接收）。默认全 GPIOA 单口：CLK=PA26/MOSI=PA25/
// MISO=PA9/CSN=PA24/CE=PA23/IRQ=PA22——与 ZIGBEE_UART（PA26/PA25）、
// UWB/DEBUG_UART（PA23/PA24/PA22）、HUIDU 巡线（PA22-26）、joystick X/Y、
// adc、DIGIT_UART（PA9）默认重叠：NRF 与其它无线/巡线/手动输入互替、同选
// 概率最低，同选时经引脚绑定消解）
NRF24L01.$name = "NRF24L01";
NRF24L01.associatedPins.create(6);
NRF24L01.associatedPins[0].$name        = "CLK";
NRF24L01.associatedPins[0].direction    = "OUTPUT";
NRF24L01.associatedPins[0].initialValue = "CLEARED";
NRF24L01.associatedPins[0].pin.$assign  = "PA26";
NRF24L01.associatedPins[1].$name        = "MOSI";
NRF24L01.associatedPins[1].direction    = "OUTPUT";
NRF24L01.associatedPins[1].initialValue = "CLEARED";
NRF24L01.associatedPins[1].pin.$assign  = "PA25";
NRF24L01.associatedPins[2].$name        = "MISO";
NRF24L01.associatedPins[2].direction    = "INPUT";
NRF24L01.associatedPins[2].pin.$assign  = "PA9";
NRF24L01.associatedPins[3].$name        = "CSN";
NRF24L01.associatedPins[3].direction    = "OUTPUT";
NRF24L01.associatedPins[3].initialValue = "SET";
NRF24L01.associatedPins[3].pin.$assign  = "PA24";
NRF24L01.associatedPins[4].$name        = "CE";
NRF24L01.associatedPins[4].direction    = "OUTPUT";
NRF24L01.associatedPins[4].initialValue = "CLEARED";
NRF24L01.associatedPins[4].pin.$assign  = "PA23";
NRF24L01.associatedPins[5].$name        = "IRQ";
NRF24L01.associatedPins[5].direction    = "INPUT";
NRF24L01.associatedPins[5].pin.$assign  = "PA22";

// 红外遥控接收（ir_remote 模块：OUT 输入（接收头输出直接接 GPIO，上拉 = 无
// 信号高电平、有信号拉低）；NEC 解码用 CPU 忙等采样（delay 模块 20us 步进），
// 不占 TIMER（TIMG 全占，sr04 先例）；主循环轮询解码、不注册 GPIO 中断
// （GROUP1 只有一路且被 motor 编码器独占——红外+电机是经典组合）。默认
// PA26——与 ZIGBEE_TX/joystick X/NRF24L01 CLK 默认重叠（红外与其它无线/
// 手动输入互替、同选概率最低），同选时经引脚绑定消解）
IR_REMOTE.$name = "IR_REMOTE";
IR_REMOTE.associatedPins.create(1);
IR_REMOTE.associatedPins[0].$name            = "OUT";
IR_REMOTE.associatedPins[0].direction        = "INPUT";
IR_REMOTE.associatedPins[0].internalResistor = "PULL_UP";
IR_REMOTE.associatedPins[0].pin.$assign      = "PA26";

// MAX7219 数码管/点阵（max7219 模块：软 SPI 位操作 3 脚 DIN/CLK/CS，全强推挽
// 输出；位操作不占硬件 SPI 外设；CS 初始高 = 片选空闲。默认 DIN=PB9（与
// DC_MOTOR AIN1 重叠）/CLK=PA18（与 DC_MOTOR AIN2 重叠——PA18 兼 BSL 排针
// 脚，作输出无碍）/CS=PB18（与 DC_MOTOR BIN1 重叠）——大数字显示（计分/
// 计时/数据牌类固定装置）与双电机小车同选概率最低（小车状态显示惯走
// OLED），同选时经引脚绑定消解）
const MAX7219 = GPIO.addInstance();
MAX7219.$name = "MAX7219";
MAX7219.associatedPins.create(3);
MAX7219.associatedPins[0].$name        = "DIN";
MAX7219.associatedPins[0].direction    = "OUTPUT";
MAX7219.associatedPins[0].initialValue = "CLEARED";
MAX7219.associatedPins[0].pin.$assign  = "PB9";
MAX7219.associatedPins[1].$name        = "CLK";
MAX7219.associatedPins[1].direction    = "OUTPUT";
MAX7219.associatedPins[1].initialValue = "CLEARED";
MAX7219.associatedPins[1].pin.$assign  = "PA18";
MAX7219.associatedPins[2].$name        = "CS";
MAX7219.associatedPins[2].direction    = "OUTPUT";
MAX7219.associatedPins[2].initialValue = "SET";
MAX7219.associatedPins[2].pin.$assign  = "PB18";

// PCA9685 16 路舵机驱动板（pca9685 模块：软 I2C 位操作 2 脚 SCL/SDA——照
// AHT10 先例不占硬件 I2C 外设；SDA 方向运行时切换（写 = 输出、读 ACK = 输入）。
// 默认 SCL=PB6 / SDA=PB7——与 STEP_MOTOR SLP2/DIR2、HUIDU R3/R4、
// AHT10 SCL/SDA（软 I2C 同型）、DHT11 DATA 重叠：16 路舵机多自由度执行与
// 温湿度采集（环境站类）/步进电机（单轴执行，互替）/8 路灰度巡线（车类）
// 同选概率最低，同选时经引脚绑定消解；软 I2C 需板上/模块自带上拉）
const PCA9685 = GPIO.addInstance();
PCA9685.$name = "PCA9685";
PCA9685.associatedPins.create(2);
PCA9685.associatedPins[0].$name        = "SCL";
PCA9685.associatedPins[0].direction    = "OUTPUT";
PCA9685.associatedPins[0].initialValue = "CLEARED";
PCA9685.associatedPins[0].pin.$assign  = "PB6";
PCA9685.associatedPins[1].$name        = "SDA";
PCA9685.associatedPins[1].direction    = "OUTPUT";
PCA9685.associatedPins[1].initialValue = "CLEARED";
PCA9685.associatedPins[1].pin.$assign  = "PB7";

// 红外编码发射（ir_remote_tx 模块：OUT 输出强推挽，38kHz NEC 载波位时序
// CPU 忙等 + delay 模块换算，不占 TIMER（照 ir_remote/ws2812 先例）；初始
// 低 = 载波空闲。默认 PA0——与 I2C_0 SDA（ml_mpu6050 姿态）/板载 LED 重叠
// （红外发射链与姿态采集同选概率最低；板载 LED 随载波闪烁可作发射指示），
// 且与 IR_REMOTE 默认 PA26 刻意错开（发射/接收本就常配对——双选默认即不撞，
// 同选时经引脚绑定消解）
const IR_TX = GPIO.addInstance();
IR_TX.$name = "IR_TX";
IR_TX.associatedPins.create(1);
IR_TX.associatedPins[0].$name        = "OUT";
IR_TX.associatedPins[0].direction    = "OUTPUT";
IR_TX.associatedPins[0].initialValue = "CLEARED";
IR_TX.associatedPins[0].pin.$assign  = "PA0";

// JQ8900 语音播报（jq8900 模块：软 UART 单发 TX——GPIO 位操作 9600 8N1，
// 不占 UART 外设/TIMER（批次 4 UART 可行性调研：SysConfig CLI 拒绝同一
// UART 外设多实例，语音单向发指令帧走软 UART）；TX 输出初始 SET = 空闲高。
// 默认 PB19——DC_MOTOR 编码器 BA 脚：语音播报与双电机小车同选概率最低，
// 同选时经引脚绑定消解；与同批 syn6288 默认 PB20 刻意错开（语音两件常同选））
const JQ8900 = GPIO.addInstance();
JQ8900.$name = "JQ8900";
JQ8900.associatedPins.create(1);
JQ8900.associatedPins[0].$name        = "TX";
JQ8900.associatedPins[0].direction    = "OUTPUT";
JQ8900.associatedPins[0].initialValue = "SET";
JQ8900.associatedPins[0].pin.$assign  = "PB19";

// SYN6288 语音合成（syn6288 模块：软 UART 单发 TX——同 jq8900 先例，不占
// UART 外设/TIMER；TX 输出初始 SET = 空闲高。默认 PB20——DC_MOTOR 编码器
// BB 脚：语音合成与双电机小车同选概率最低；与同批 jq8900 默认 PB19 刻意
// 错开（语音两件常同选，默认即不撞），同选时经引脚绑定消解）
const SYN6288 = GPIO.addInstance();
SYN6288.$name = "SYN6288";
SYN6288.associatedPins.create(1);
SYN6288.associatedPins[0].$name        = "TX";
SYN6288.associatedPins[0].direction    = "OUTPUT";
SYN6288.associatedPins[0].initialValue = "SET";
SYN6288.associatedPins[0].pin.$assign  = "PB20";

// RC522 射频 IC 卡识别（rc522 模块：软 SPI 位操作 5 脚——CS/RST/SCK/MOSI
// 输出 + MISO 输入，单 RC522_PORT 宏；不占硬件 SPI 外设（nrf24l01 先例）。
// 默认 CS=PA7（DC_MOTOR BIN2 + SERVO_PWM 重叠）/RST=PA18（DC_MOTOR AIN2 +
// MAX7219 CLK）/SCK=PA14（DCC_100_PWM2 + WS2812 IN）/MOSI=PA16（编码器
// AA）/MISO=PA17（编码器 AB）——读卡与车类（双电机/舵机/步进）同选概率
// 最低，同选时经引脚绑定消解；五脚全 GPIOA 单口，与同批语音/指纹默认不撞）
const RC522 = GPIO.addInstance();
RC522.$name = "RC522";
RC522.associatedPins.create(5);
RC522.associatedPins[0].$name        = "CS";
RC522.associatedPins[0].direction    = "OUTPUT";
RC522.associatedPins[0].initialValue = "SET";
RC522.associatedPins[0].pin.$assign  = "PA7";
RC522.associatedPins[1].$name        = "RST";
RC522.associatedPins[1].direction    = "OUTPUT";
RC522.associatedPins[1].initialValue = "SET";
RC522.associatedPins[1].pin.$assign  = "PA18";
RC522.associatedPins[2].$name        = "SCK";
RC522.associatedPins[2].direction    = "OUTPUT";
RC522.associatedPins[2].initialValue = "SET";
RC522.associatedPins[2].pin.$assign  = "PA14";
RC522.associatedPins[3].$name        = "MOSI";
RC522.associatedPins[3].direction    = "OUTPUT";
RC522.associatedPins[3].initialValue = "CLEARED";
RC522.associatedPins[3].pin.$assign  = "PA16";
RC522.associatedPins[4].$name        = "MISO";
RC522.associatedPins[4].direction    = "INPUT";
RC522.associatedPins[4].pin.$assign  = "PA17";

// 指纹模块触摸感应输入（fingerprint 模块：模块 5 脚触摸信号输出高 = 检测到
// 触摸，VTI 接 3.3V——直连 GPIO 输入即可。默认 PA12——PWMAB C0（motor 双路
// PWM）+ BH1750 SCL 重叠：指纹与双电机/光照同选概率最低，同选时经引脚绑定
// 消解；与同批 jq8900/syn6288/rc522 默认不撞）
const FINGERPRINT = GPIO.addInstance();
FINGERPRINT.$name = "FINGERPRINT";
FINGERPRINT.associatedPins.create(1);
FINGERPRINT.associatedPins[0].$name        = "TOUCH";
FINGERPRINT.associatedPins[0].direction    = "INPUT";
FINGERPRINT.associatedPins[0].pin.$assign  = "PA12";

// LED/蜂鸣器输出（PA15；原 LaunchPad 值 PA3 = 32.768k 晶振脚，地猛星排针未引出）
LED_BEEP.$name = "LED_BEEP";
LED_BEEP.associatedPins.create(1);
LED_BEEP.associatedPins[0].$name        = "LED";
LED_BEEP.associatedPins[0].direction    = "OUTPUT";
LED_BEEP.associatedPins[0].initialValue = "CLEARED";
LED_BEEP.associatedPins[0].pin.$assign  = "PA15";

// 步进电机方向/使能（step_motor 模块：宏 STEP_MOTOR_RST2/SLP2/DIR2/DCY2_PIN，
// 四脚同 GPIOB → STEP_MOTOR_PORT = GPIOB；RST2/SLP2 空闲高有效，init 置高）
STEP_MOTOR.$name = "STEP_MOTOR";
STEP_MOTOR.associatedPins.create(4);
STEP_MOTOR.associatedPins[0].$name        = "RST2";
STEP_MOTOR.associatedPins[0].direction    = "OUTPUT";
STEP_MOTOR.associatedPins[0].initialValue = "SET";
STEP_MOTOR.associatedPins[0].pin.$assign  = "PB24";
STEP_MOTOR.associatedPins[1].$name        = "SLP2";
STEP_MOTOR.associatedPins[1].direction    = "OUTPUT";
STEP_MOTOR.associatedPins[1].initialValue = "SET";
STEP_MOTOR.associatedPins[1].pin.$assign  = "PB6";
STEP_MOTOR.associatedPins[2].$name        = "DIR2";
STEP_MOTOR.associatedPins[2].direction    = "OUTPUT";
STEP_MOTOR.associatedPins[2].initialValue = "CLEARED";
STEP_MOTOR.associatedPins[2].pin.$assign  = "PB7";
STEP_MOTOR.associatedPins[3].$name        = "DCY2";
STEP_MOTOR.associatedPins[3].direction    = "OUTPUT";
STEP_MOTOR.associatedPins[3].initialValue = "CLEARED";
STEP_MOTOR.associatedPins[3].pin.$assign  = "PB8";

// IMU 串口（RX 中断；UART0 = PA28(TX)/PA31(RX)——板载 CH340E 占用 UART0 默认脚
// PA10/PA11，勿用；imu_uart 模块接线注释同步此值）
IMU601.$name             = "IMU601";
IMU601.profile           = "CONFIG_PROFILE_1";
IMU601.peripheral.$assign = "UART0";
IMU601.uartClkSrc        = "BUSCLK";
IMU601.ovsRate           = "16";
IMU601.targetBaudRate    = 115200;
IMU601.enableInternalLoopback = false;
IMU601.enabledInterrupts = ["RX"];
IMU601.enableFIFO        = false;
IMU601.peripheral.rxPin.$assign = "PA31";
IMU601.peripheral.txPin.$assign = "PA28";

// K230 视觉串口（digit_uart/coord_detect 模块用，RX 中断；PA8/PA9 = UART1）
const DIGIT_UART = UART.addInstance();
DIGIT_UART.$name             = "DIGIT_UART";
DIGIT_UART.profile           = "CONFIG_PROFILE_1";
DIGIT_UART.peripheral.$assign = "UART1";
DIGIT_UART.uartClkSrc        = "BUSCLK";
DIGIT_UART.ovsRate           = "16";
DIGIT_UART.targetBaudRate    = 115200;
DIGIT_UART.enableInternalLoopback = false;
DIGIT_UART.enabledInterrupts = ["RX"];
DIGIT_UART.enableFIFO        = false;
DIGIT_UART.peripheral.rxPin.$assign = "PA9";
DIGIT_UART.peripheral.txPin.$assign = "PA8";

// 调试串口（debug_uart 模块用，RX 中断；UART2 = PA23(TX)/PA22(RX)。
// 与 UWB_UART 默认同 UART2——两模块同选时经引脚绑定换实例消解；
// PA23/PA22 与 HUIDU L2/L1 默认重叠，同选时改绑消解）
const DEBUG_UART = UART.addInstance();
DEBUG_UART.$name             = "DEBUG_UART";
DEBUG_UART.profile           = "CONFIG_PROFILE_1";
DEBUG_UART.peripheral.$assign = "UART2";
DEBUG_UART.uartClkSrc        = "BUSCLK";
DEBUG_UART.ovsRate           = "16";
DEBUG_UART.targetBaudRate    = 115200;
DEBUG_UART.enableInternalLoopback = false;
DEBUG_UART.enabledInterrupts = ["RX"];
DEBUG_UART.enableFIFO        = false;
DEBUG_UART.peripheral.rxPin.$assign = "PA22";
DEBUG_UART.peripheral.txPin.$assign = "PA23";

// UWB 定位串口（uwb_uart 模块用，RX 中断；UART2 = PA23(TX)/PA24(RX)。
// PA23/PA24 与 HUIDU L2/L3 默认重叠——两模块同选时经引脚绑定消解）
const UWB_UART = UART.addInstance();
UWB_UART.$name             = "UWB_UART";
UWB_UART.profile           = "CONFIG_PROFILE_1";
UWB_UART.peripheral.$assign = "UART2";
UWB_UART.uartClkSrc        = "BUSCLK";
UWB_UART.ovsRate           = "16";
UWB_UART.targetBaudRate    = 115200;
UWB_UART.enableInternalLoopback = false;
UWB_UART.enabledInterrupts = ["RX"];
UWB_UART.enableFIFO        = false;
UWB_UART.peripheral.rxPin.$assign = "PA24";
UWB_UART.peripheral.txPin.$assign = "PA23";

// Zigbee DL-20 串口（zigbee_uart 接收 / zigbee_uart_key 发送共享，
// RX 中断；UART3 = PA26(TX)/PA25(RX)。PA26/PA25 与 HUIDU R2/R3 默认
// 重叠——同选时经引脚绑定消解）
const ZIGBEE_UART = UART.addInstance();
ZIGBEE_UART.$name             = "ZIGBEE_UART";
ZIGBEE_UART.profile           = "CONFIG_PROFILE_1";
ZIGBEE_UART.peripheral.$assign = "UART3";
ZIGBEE_UART.uartClkSrc        = "BUSCLK";
ZIGBEE_UART.ovsRate           = "16";
ZIGBEE_UART.targetBaudRate    = 115200;
ZIGBEE_UART.enableInternalLoopback = false;
ZIGBEE_UART.enabledInterrupts = ["RX"];
ZIGBEE_UART.enableFIFO        = false;
ZIGBEE_UART.peripheral.rxPin.$assign = "PA25";
ZIGBEE_UART.peripheral.txPin.$assign = "PA26";

// HC05 蓝牙串口（hc05 模块：9600 8N1 透传——HC05 模块出厂默认波特率，与
// 其余 UART 实例 115200 独立无冲突；RX 中断 + FIFO 关闭；与 DEBUG_UART/
// UWB_UART 默认同 UART2 外设——两模块同选时经引脚绑定换实例消解；默认
// TX=PA23/RX=PA24 与 UWB_UART 同脚：蓝牙手机遥控与 UWB 定位链路互替、
// 同选概率最低，同选时经引脚绑定消解）
const HC05_UART = UART.addInstance();
HC05_UART.$name             = "HC05_UART";
HC05_UART.profile           = "CONFIG_PROFILE_1";
HC05_UART.peripheral.$assign = "UART2";
HC05_UART.uartClkSrc        = "BUSCLK";
HC05_UART.ovsRate           = "16";
HC05_UART.targetBaudRate    = 9600;
HC05_UART.enableInternalLoopback = false;
HC05_UART.enabledInterrupts = ["RX"];
HC05_UART.enableFIFO        = false;
HC05_UART.peripheral.rxPin.$assign = "PA24";
HC05_UART.peripheral.txPin.$assign = "PA23";

// 指纹识别（fingerprint 模块：AS608 串口双向——独立 UART 实例，批次 4 UART
// 可行性调研实证 SysConfig CLI 拒绝同一 UART 外设多实例，故不共享；默认
// UART0（IMU601 原脚 PA28/PA31——身份与姿态同选概率最低，单选裁剪后独占
// UART0，同选时经引脚绑定换实例消解）；57600 = 页面注释 AS608 默认波特率
// （市售 9600 出厂版改 targetBaudRate 一行即可，协议与波特率无关）；
// enabledInterrupts 空 = **轮询接收**（不注册 UART 中断、无 ISR 强符号）
const FINGERPRINT_UART = UART.addInstance();
FINGERPRINT_UART.$name             = "FINGERPRINT_UART";
FINGERPRINT_UART.profile           = "CONFIG_PROFILE_1";
FINGERPRINT_UART.peripheral.$assign = "UART0";
FINGERPRINT_UART.uartClkSrc        = "BUSCLK";
FINGERPRINT_UART.ovsRate           = "16";
FINGERPRINT_UART.targetBaudRate    = 57600;
FINGERPRINT_UART.enableInternalLoopback = false;
FINGERPRINT_UART.enabledInterrupts = [];
FINGERPRINT_UART.enableFIFO        = false;
FINGERPRINT_UART.peripheral.rxPin.$assign = "PA31";
FINGERPRINT_UART.peripheral.txPin.$assign = "PA28";

// OLED（I2C 控制器）
OLED.$name                         = "OLED";
OLED.basicEnableController         = true;
OLED.basicControllerBusSpeed       = 400000;
OLED.intController                 = ["NACK", "TX_DONE"];
OLED.advAnalogGlitchFilter         = "DISABLED";
OLED.peripheral.$assign            = "I2C1";
OLED.peripheral.sdaPin.$assign     = "PB3";
OLED.peripheral.sclPin.$assign     = "PB2";

// MPU6050 姿态传感器（ml_mpu6050 模块：I2C_0_INST，轮询控制器模式；
// I2C0 = PA0(SDA)/PA1(SCL) 复用板载 LED 脚，通信期间 LED 微闪——地猛星 I2C0 的
// 另一组 PA28/PA31 已给 IMU601 UART0；PA1 板载 4.7k 上拉，PA0 上拉未焊 R12、
// 依赖 MPU6050 模块板自带）
I2C_0.$name                     = "I2C_0";
I2C_0.basicEnableController     = true;
I2C_0.basicControllerBusSpeed   = 400000;
I2C_0.peripheral.$assign        = "I2C0";
I2C_0.peripheral.sdaPin.$assign = "PA0";
I2C_0.peripheral.sclPin.$assign = "PA1";

// adc 模块 + 摇杆 + 模拟量测距 + 气体传感 + 火焰/土壤传感共享 ADC12_0（b1-adc-servo/01 +
// wiki-modules-batch1/01 + wiki-modules-batch2/02/04 +
// wiki-modules-batch7/01/02 + wiki-modules-batch8/01/02：
// MEM0=PA24/A0_3 归 adc（us016/mq2 薄封装共读同槽——wiki-modules-batch2/02
// 与 batch6/03），MEM1=PA26/A0_1、
// MEM2=PA25/A0_2 归 joystick X/Y，MEM3=PA27/A0_0 归 ir_distance 红外测距
// （手册原脚），MEM4=PB20/A0_6 归 mq135、MEM5=PB24/A0_5 归 mq5（独立通道
// ——与 mq2 的 MEM0 薄封装不同：多路气体同选时各器件物理通道独立、无共读
// 冲突；2026-09-08 SysConfig CLI 实证 MEM4-7 通道/脚全合法），MEM6=PA22/A0_7
// 归 flame 火焰传感（独立通道——火焰 AO 为高阻电流源，取剩余通道中唯一
// 无负载脚 PA22；与 HUIDU L1/DEBUG_UART RX/NRF24L01 IRQ/TTP224 OUT1 重叠，
// 与巡线/无线/触摸不同框、同选概率最低），MEM7=PA14/A0_12 归 soil 土壤湿度
// （独立通道——**MEM 槽位已满（8/8）**：后续 ADC 类件（photoresistance/rain/
// gp2y1014au/s12sd/ms1100）一律薄封装共读 MEM0（mq2/us016 先例——多件同选
// 同读一物理通道、一次转换一次读、采样节奏按用途自协调）；PA14 板载
// LED2+15k 为固定比率衰减（读数系统偏小、单调性保留），与 DCC_100_PWM2/
// WS2812 IN/RC522 SCK/AGS10 SDA 重叠——浇花/智慧农业与运动/读卡/气体不同框、
// 同选概率最低）；
// 轮询读取不配
// 中断。多 MEM 必须 sequence 模式（startAdd..endAdd = 启用 MEM 集合）——
// 单发模式只启用 startAdd 槽位，adcPin1/2 由此不可用（原注释「槽位不存在」
// 系误判，2026-09-05 SysConfig CLI 实证）
const ADC12   = scripting.addModule("/ti/driverlib/ADC12", {}, false);
const ADC12_0 = ADC12.addInstance();
ADC12_0.$name                      = "ADC12_0";
ADC12_0.sampClkSrc                 = "DL_ADC12_CLOCK_ULPCLK";
ADC12_0.sampClkDiv                 = "DL_ADC12_CLOCK_DIVIDE_8";
ADC12_0.sampleTime0                = "125 us";
ADC12_0.powerDownMode              = "DL_ADC12_POWER_DOWN_MODE_MANUAL";
ADC12_0.adcMem0chansel             = "DL_ADC12_INPUT_CHAN_3";
ADC12_0.adcMem1chansel             = "DL_ADC12_INPUT_CHAN_1";
ADC12_0.adcMem2chansel             = "DL_ADC12_INPUT_CHAN_2";
ADC12_0.adcMem3chansel             = "DL_ADC12_INPUT_CHAN_0";
ADC12_0.adcMem4chansel             = "DL_ADC12_INPUT_CHAN_6";
ADC12_0.adcMem5chansel             = "DL_ADC12_INPUT_CHAN_5";
ADC12_0.adcMem6chansel             = "DL_ADC12_INPUT_CHAN_7";
ADC12_0.adcMem7chansel             = "DL_ADC12_INPUT_CHAN_12";
ADC12_0.samplingOperationMode      = "sequence";
ADC12_0.startAdd                   = 0;
ADC12_0.endAdd                     = 7;
ADC12_0.peripheral.$assign         = "ADC0";
ADC12_0.peripheral.adcPin3.$assign = "PA24";
ADC12_0.peripheral.adcPin1.$assign  = "PA26";
ADC12_0.peripheral.adcPin2.$assign  = "PA25";
ADC12_0.peripheral.adcPin0.$assign = "PA27";
ADC12_0.peripheral.adcPin6.$assign = "PB20";
ADC12_0.peripheral.adcPin5.$assign = "PB24";
ADC12_0.peripheral.adcPin7.$assign = "PA22";
ADC12_0.peripheral.adcPin12.$assign = "PA14";
const Board = scripting.addModule("/ti/driverlib/Board", {}, false);
Board.configureUnused = true;

SYSCTL.forceDefaultClkConfig = true;
SYSCTL.clockTreeEn  = true;
